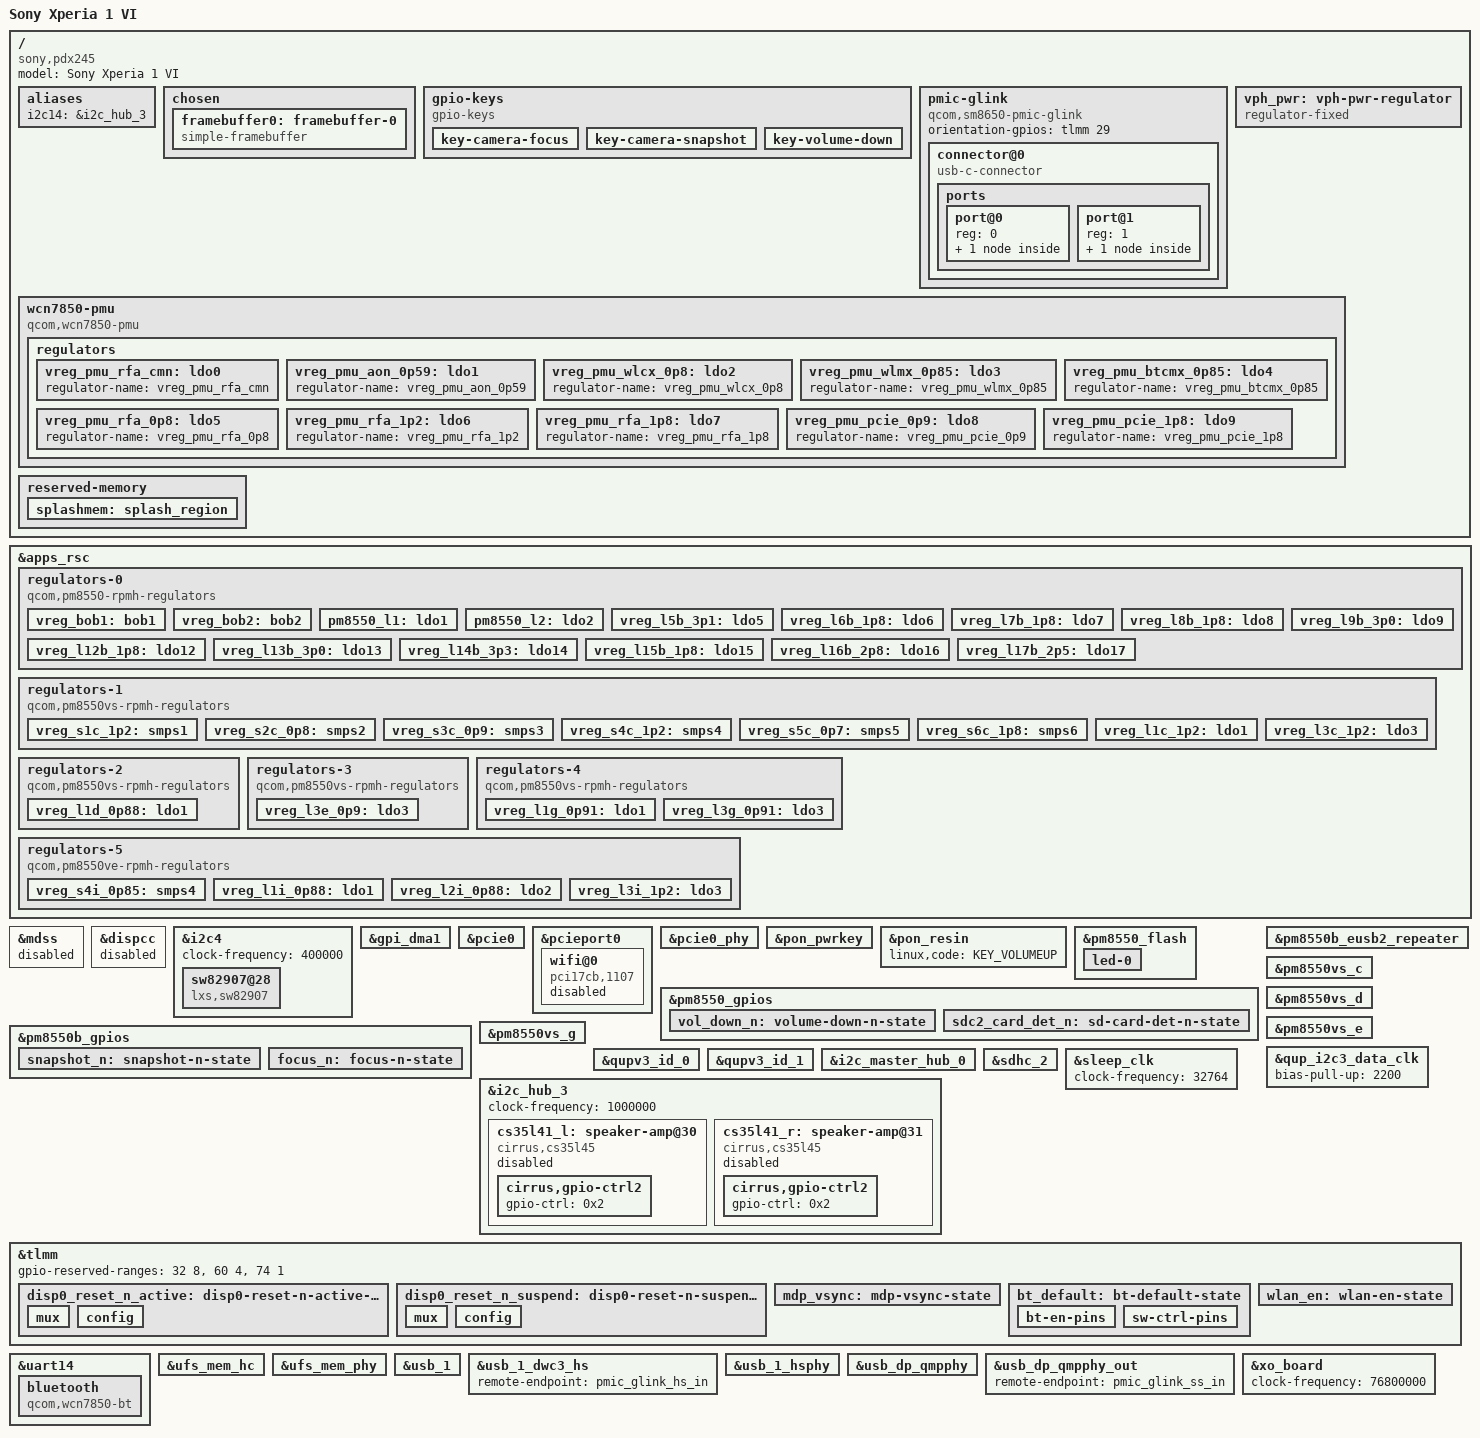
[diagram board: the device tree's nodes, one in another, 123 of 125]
// SPDX-License-Identifier: GPL-2.0 OR BSD-3-Clause
/*
 * Sony Xperia 1 VI (pdx245/XQ-EC54) device tree source
 *
 * Copyright (c) 2026, Igor Belwon <igor.belwon@mentallysanemainliners.org>
 */

/dts-v1/;

#include <dt-bindings/leds/common.h>
#include <dt-bindings/regulator/qcom,rpmh-regulator.h>
#include <dt-bindings/sound/cs35l45.h>
#include "sm8650.dtsi"
#include "pm8010.dtsi"
#include "pm8550.dtsi"
#include "pm8550b.dtsi"
#define PMK8550VE_SID 8
#include "pm8550ve.dtsi"
#include "pm8550vs.dtsi"
#include "pmk8550.dtsi"
#include "pmr735d_a.dtsi"

/ {
	model = "Sony Xperia 1 VI";
	compatible = "sony,pdx245", "qcom,sm8650";

	aliases {
		i2c14 = &i2c_hub_3;
	};

	chosen {
		bootargs = "clk_ignore_unused pd_ignore_unused console=tty0";
		#address-cells = <2>;
		#size-cells = <2>;
		ranges;

		stdout-path = "framebuffer0";

		framebuffer0: framebuffer-0 {
			compatible = "simple-framebuffer";
			memory-region = <&splashmem>;

			width = <1080>;
			height = <2340>;
			stride = <(1080 * 4)>;
			format = "a8r8g8b8";
		};
	};

	gpio-keys {
		compatible = "gpio-keys";
		label = "gpio-keys";

		pinctrl-0 = <&focus_n &snapshot_n &vol_down_n>;
		pinctrl-names = "default";

		key-camera-focus {
			label = "Camera Focus";
			linux,code = <KEY_CAMERA_FOCUS>;
			gpios = <&pm8550b_gpios 8 GPIO_ACTIVE_LOW>;
			debounce-interval = <15>;
			linux,can-disable;
			wakeup-source;
		};

		key-camera-snapshot {
			label = "Camera Snapshot";
			gpios = <&pm8550b_gpios 7 GPIO_ACTIVE_LOW>;
			linux,code = <KEY_CAMERA>;
			debounce-interval = <15>;
			linux,can-disable;
			wakeup-source;
		};

		key-volume-down {
			label = "Volume Down";
			linux,code = <KEY_VOLUMEDOWN>;
			gpios = <&pm8550_gpios 6 GPIO_ACTIVE_LOW>;
			debounce-interval = <15>;
			linux,can-disable;
			wakeup-source;
		};
	};

	pmic-glink {
		compatible = "qcom,sm8650-pmic-glink",
			     "qcom,sm8550-pmic-glink",
			     "qcom,pmic-glink";
		orientation-gpios = <&tlmm 29 GPIO_ACTIVE_HIGH>;
		#address-cells = <1>;
		#size-cells = <0>;

		connector@0 {
			compatible = "usb-c-connector";
			reg = <0>;
			power-role = "dual";
			data-role = "dual";

			ports {
				#address-cells = <1>;
				#size-cells = <0>;

				port@0 {
					reg = <0>;

					pmic_glink_hs_in: endpoint {
						remote-endpoint = <&usb_1_dwc3_hs>;
					};
				};

				port@1 {
					reg = <1>;

					pmic_glink_ss_in: endpoint {
						remote-endpoint = <&usb_dp_qmpphy_out>;
					};
				};
			};
		};
	};

	vph_pwr: vph-pwr-regulator {
		compatible = "regulator-fixed";

		regulator-name = "vph_pwr";
		regulator-min-microvolt = <3700000>;
		regulator-max-microvolt = <3700000>;

		regulator-always-on;
		regulator-boot-on;
	};

	wcn7850-pmu {
		compatible = "qcom,wcn7850-pmu";

		pinctrl-names = "default";
		pinctrl-0 = <&wlan_en>, <&bt_default>;

		wlan-enable-gpios = <&tlmm 16 GPIO_ACTIVE_HIGH>;
		bt-enable-gpios = <&tlmm 17 GPIO_ACTIVE_HIGH>;

		vdd-supply = <&vreg_s4i_0p85>;
		vddio-supply = <&vreg_l15b_1p8>;
		vddio1p2-supply = <&vreg_l3c_1p2>;
		vddaon-supply = <&vreg_s2c_0p8>;
		vdddig-supply = <&vreg_s3c_0p9>;
		vddrfa1p2-supply = <&vreg_s1c_1p2>;
		vddrfa1p8-supply = <&vreg_s6c_1p8>;

		clocks = <&rpmhcc RPMH_RF_CLK1>;

		regulators {
			vreg_pmu_rfa_cmn: ldo0 {
				regulator-name = "vreg_pmu_rfa_cmn";
			};

			vreg_pmu_aon_0p59: ldo1 {
				regulator-name = "vreg_pmu_aon_0p59";
			};

			vreg_pmu_wlcx_0p8: ldo2 {
				regulator-name = "vreg_pmu_wlcx_0p8";
			};

			vreg_pmu_wlmx_0p85: ldo3 {
				regulator-name = "vreg_pmu_wlmx_0p85";
			};

			vreg_pmu_btcmx_0p85: ldo4 {
				regulator-name = "vreg_pmu_btcmx_0p85";
			};

			vreg_pmu_rfa_0p8: ldo5 {
				regulator-name = "vreg_pmu_rfa_0p8";
			};

			vreg_pmu_rfa_1p2: ldo6 {
				regulator-name = "vreg_pmu_rfa_1p2";
			};

			vreg_pmu_rfa_1p8: ldo7 {
				regulator-name = "vreg_pmu_rfa_1p8";
			};

			vreg_pmu_pcie_0p9: ldo8 {
				regulator-name = "vreg_pmu_pcie_0p9";
			};

			vreg_pmu_pcie_1p8: ldo9 {
				regulator-name = "vreg_pmu_pcie_1p8";
			};
		};
	};

	reserved-memory {
		splashmem: splash_region {
			reg = <0x00 0xd5100000 0x00 0x2b00000>;
			no-map;
		};
	};
};

&apps_rsc {
	regulators-0 {
		compatible = "qcom,pm8550-rpmh-regulators";

		vdd-bob1-supply = <&vph_pwr>;
		vdd-bob2-supply = <&vph_pwr>;
		vdd-l2-l13-l14-supply = <&vreg_bob1>;
		vdd-l3-supply = <&vreg_s1c_1p2>;
		vdd-l5-l16-supply = <&vreg_bob1>;
		vdd-l6-l7-supply = <&vreg_bob1>;
		vdd-l8-l9-supply = <&vreg_bob1>;
		vdd-l11-supply = <&vreg_s1c_1p2>;
		vdd-l12-supply = <&vreg_s6c_1p8>;
		vdd-l15-supply = <&vreg_s6c_1p8>;
		vdd-l17-supply = <&vreg_bob2>;

		qcom,pmic-id = "b";

		vreg_bob1: bob1 {
			regulator-name = "vreg_bob1";
			regulator-min-microvolt = <3400000>;
			regulator-max-microvolt = <3960000>;
			regulator-initial-mode = <RPMH_REGULATOR_MODE_HPM>;
		};

		vreg_bob2: bob2 {
			regulator-name = "vreg_bob2";
			regulator-min-microvolt = <2704000>;
			regulator-max-microvolt = <3008000>;
			regulator-initial-mode = <RPMH_REGULATOR_MODE_HPM>;
		};

		pm8550_l1: ldo1 {
			regulator-name = "pm8550_l1";
			regulator-min-microvolt = <1800000>;
			regulator-max-microvolt = <1800000>;
			regulator-initial-mode = <RPMH_REGULATOR_MODE_HPM>;
		};

		pm8550_l2: ldo2 {
			regulator-name = "pm8550_l2";
			regulator-min-microvolt = <3008000>;
			regulator-max-microvolt = <3008000>;
			regulator-initial-mode = <RPMH_REGULATOR_MODE_HPM>;
		};

		vreg_l5b_3p1: ldo5 {
			regulator-name = "vreg_l5b_3p1";
			regulator-min-microvolt = <3104000>;
			regulator-max-microvolt = <3104000>;
			regulator-initial-mode = <RPMH_REGULATOR_MODE_HPM>;
			regulator-allow-set-load;
			regulator-allowed-modes = <RPMH_REGULATOR_MODE_LPM
						   RPMH_REGULATOR_MODE_HPM>;
		};

		vreg_l6b_1p8: ldo6 {
			regulator-name = "vreg_l6b_1p8";
			regulator-min-microvolt = <1800000>;
			regulator-max-microvolt = <3008000>;
			regulator-initial-mode = <RPMH_REGULATOR_MODE_HPM>;
			regulator-allow-set-load;
			regulator-allowed-modes = <RPMH_REGULATOR_MODE_LPM
						   RPMH_REGULATOR_MODE_HPM>;
		};

		vreg_l7b_1p8: ldo7 {
			regulator-name = "vreg_l7b_1p8";
			regulator-min-microvolt = <1800000>;
			regulator-max-microvolt = <3008000>;
			regulator-initial-mode = <RPMH_REGULATOR_MODE_HPM>;
		};

		vreg_l8b_1p8: ldo8 {
			regulator-name = "vreg_l8b_1p8";
			regulator-min-microvolt = <1800000>;
			regulator-max-microvolt = <3008000>;
			regulator-initial-mode = <RPMH_REGULATOR_MODE_HPM>;
			regulator-allow-set-load;
			regulator-allowed-modes = <RPMH_REGULATOR_MODE_LPM
						   RPMH_REGULATOR_MODE_HPM>;
		};

		vreg_l9b_3p0: ldo9 {
			regulator-name = "pm8550_l9";
			regulator-min-microvolt = <2960000>;
			regulator-max-microvolt = <3008000>;
			regulator-initial-mode = <RPMH_REGULATOR_MODE_HPM>;
		};

		vreg_l12b_1p8: ldo12 {
			regulator-name = "vreg_l12b_1p8";
			regulator-min-microvolt = <1800000>;
			regulator-max-microvolt = <1800000>;
			regulator-initial-mode = <RPMH_REGULATOR_MODE_HPM>;
			regulator-allow-set-load;
			regulator-allowed-modes = <RPMH_REGULATOR_MODE_LPM
						   RPMH_REGULATOR_MODE_HPM>;
		};

		vreg_l13b_3p0: ldo13 {
			regulator-name = "vreg_l13b_3p0";
			regulator-min-microvolt = <3000000>;
			regulator-max-microvolt = <3000000>;
			regulator-initial-mode = <RPMH_REGULATOR_MODE_HPM>;
			regulator-allow-set-load;
			regulator-allowed-modes = <RPMH_REGULATOR_MODE_LPM
						   RPMH_REGULATOR_MODE_HPM>;
		};

		vreg_l14b_3p3: ldo14 {
			regulator-name = "vreg_l14b_3p3";
			regulator-min-microvolt = <3008000>;
			regulator-max-microvolt = <3008000>;
			regulator-initial-mode = <RPMH_REGULATOR_MODE_HPM>;
			regulator-allow-set-load;
			regulator-allowed-modes = <RPMH_REGULATOR_MODE_LPM
						   RPMH_REGULATOR_MODE_HPM>;
		};

		vreg_l15b_1p8: ldo15 {
			regulator-name = "vreg_l15b_1p8";
			regulator-min-microvolt = <1800000>;
			regulator-max-microvolt = <1800000>;
			regulator-initial-mode = <RPMH_REGULATOR_MODE_HPM>;
			regulator-allow-set-load;
			regulator-allowed-modes = <RPMH_REGULATOR_MODE_LPM
						   RPMH_REGULATOR_MODE_HPM>;
		};

		vreg_l16b_2p8: ldo16 {
			regulator-name = "vreg_l16b_2p8";
			regulator-min-microvolt = <2800000>;
			regulator-max-microvolt = <2800000>;
			regulator-initial-mode = <RPMH_REGULATOR_MODE_HPM>;
			regulator-allow-set-load;
			regulator-allowed-modes = <RPMH_REGULATOR_MODE_LPM
						   RPMH_REGULATOR_MODE_HPM>;
		};

		vreg_l17b_2p5: ldo17 {
			regulator-name = "vreg_l17b_2p5";
			regulator-min-microvolt = <2504000>;
			regulator-max-microvolt = <2504000>;
			regulator-initial-mode = <RPMH_REGULATOR_MODE_HPM>;
			regulator-allow-set-load;
			regulator-allowed-modes = <RPMH_REGULATOR_MODE_LPM
						   RPMH_REGULATOR_MODE_HPM>;
		};
	};

	regulators-1 {
		compatible = "qcom,pm8550vs-rpmh-regulators";

		vdd-l1-supply = <&vreg_s1c_1p2>;
		vdd-l2-supply = <&vreg_s1c_1p2>;
		vdd-l3-supply = <&vreg_s1c_1p2>;
		vdd-s1-supply = <&vph_pwr>;
		vdd-s2-supply = <&vph_pwr>;
		vdd-s3-supply = <&vph_pwr>;
		vdd-s4-supply = <&vph_pwr>;
		vdd-s5-supply = <&vph_pwr>;
		vdd-s6-supply = <&vph_pwr>;

		qcom,pmic-id = "c";

		vreg_s1c_1p2: smps1 {
			regulator-name = "vreg_s1c_1p2";
			regulator-min-microvolt = <1224000>;
			regulator-max-microvolt = <1348000>;
			regulator-initial-mode = <RPMH_REGULATOR_MODE_HPM>;
		};

		vreg_s2c_0p8: smps2 {
			regulator-name = "vreg_s2c_0p8";
			regulator-min-microvolt = <500000>;
			regulator-max-microvolt = <1036000>;
			regulator-initial-mode = <RPMH_REGULATOR_MODE_HPM>;
		};

		vreg_s3c_0p9: smps3 {
			regulator-name = "vreg_s3c_0p9";
			regulator-min-microvolt = <904000>;
			regulator-max-microvolt = <1064000>;
			regulator-initial-mode = <RPMH_REGULATOR_MODE_HPM>;
		};

		vreg_s4c_1p2: smps4 {
			regulator-name = "vreg_s4c_1p2";
			regulator-min-microvolt = <1200000>;
			regulator-max-microvolt = <1280000>;
			regulator-initial-mode = <RPMH_REGULATOR_MODE_HPM>;
		};

		vreg_s5c_0p7: smps5 {
			regulator-name = "vreg_s5c_0p7";
			regulator-min-microvolt = <300000>;
			regulator-max-microvolt = <900000>;
			regulator-initial-mode = <RPMH_REGULATOR_MODE_HPM>;
		};

		vreg_s6c_1p8: smps6 {
			regulator-name = "vreg_s6c_1p8";
			regulator-min-microvolt = <1856000>;
			regulator-max-microvolt = <2000000>;
			regulator-initial-mode = <RPMH_REGULATOR_MODE_HPM>;
		};

		vreg_l1c_1p2: ldo1 {
			regulator-name = "vreg_l1c_1p2";
			regulator-min-microvolt = <1200000>;
			regulator-max-microvolt = <1200000>;
			regulator-initial-mode = <RPMH_REGULATOR_MODE_HPM>;
			regulator-allow-set-load;
			regulator-allowed-modes = <RPMH_REGULATOR_MODE_LPM
						   RPMH_REGULATOR_MODE_HPM>;
		};

		vreg_l3c_1p2: ldo3 {
			regulator-name = "vreg_l3c_1p2";
			regulator-min-microvolt = <1200000>;
			regulator-max-microvolt = <1200000>;
			regulator-initial-mode = <RPMH_REGULATOR_MODE_HPM>;
			regulator-allow-set-load;
			regulator-allowed-modes = <RPMH_REGULATOR_MODE_LPM
						   RPMH_REGULATOR_MODE_HPM>;
		};
	};

	regulators-2 {
		compatible = "qcom,pm8550vs-rpmh-regulators";

		vdd-l1-supply = <&vreg_s3c_0p9>;

		qcom,pmic-id = "d";

		vreg_l1d_0p88: ldo1 {
			regulator-name = "vreg_l1d_0p88";
			regulator-min-microvolt = <880000>;
			regulator-max-microvolt = <920000>;
			regulator-initial-mode = <RPMH_REGULATOR_MODE_HPM>;
			regulator-allow-set-load;
			regulator-allowed-modes = <RPMH_REGULATOR_MODE_LPM
						   RPMH_REGULATOR_MODE_HPM>;
		};
	};

	regulators-3 {
		compatible = "qcom,pm8550vs-rpmh-regulators";

		vdd-l3-supply = <&vreg_s3c_0p9>;

		qcom,pmic-id = "e";

		vreg_l3e_0p9: ldo3 {
			regulator-name = "vreg_l3e_0p9";
			regulator-min-microvolt = <880000>;
			regulator-max-microvolt = <920000>;
			regulator-initial-mode = <RPMH_REGULATOR_MODE_HPM>;
			regulator-allow-set-load;
			regulator-allowed-modes = <RPMH_REGULATOR_MODE_LPM
						   RPMH_REGULATOR_MODE_HPM>;
		};
	};

	regulators-4 {
		compatible = "qcom,pm8550vs-rpmh-regulators";

		vdd-l1-supply = <&vreg_s3c_0p9>;
		vdd-l3-supply = <&vreg_s3c_0p9>;

		qcom,pmic-id = "g";

		vreg_l1g_0p91: ldo1 {
			regulator-name = "vreg_l1g_0p91";
			regulator-min-microvolt = <912000>;
			regulator-max-microvolt = <920000>;
			regulator-initial-mode = <RPMH_REGULATOR_MODE_HPM>;
			regulator-allow-set-load;
			regulator-allowed-modes = <RPMH_REGULATOR_MODE_LPM
						   RPMH_REGULATOR_MODE_HPM>;
		};

		/*vreg_l2g_1p7: ldo2 {
			regulator-name = "vreg_l3g_0p91";
			regulator-min-microvolt = <1700000>;
			regulator-max-microvolt = <1700000>;
			regulator-initial-mode = <RPMH_REGULATOR_MODE_HPM>;
			regulator-allow-set-load;
			regulator-allowed-modes = <RPMH_REGULATOR_MODE_LPM
			RPMH_REGULATOR_MODE_HPM>;
		};*/

		vreg_l3g_0p91: ldo3 {
			regulator-name = "vreg_l3g_0p91";
			regulator-min-microvolt = <880000>;
			regulator-max-microvolt = <912000>;
			regulator-initial-mode = <RPMH_REGULATOR_MODE_HPM>;
			regulator-allow-set-load;
			regulator-allowed-modes = <RPMH_REGULATOR_MODE_LPM
						   RPMH_REGULATOR_MODE_HPM>;
		};
	};

	regulators-5 {
		compatible = "qcom,pm8550ve-rpmh-regulators";

		vdd-l1-supply = <&vreg_s3c_0p9>;
		vdd-l2-supply = <&vreg_s3c_0p9>;
		vdd-l3-supply = <&vreg_s1c_1p2>;
		vdd-s4-supply = <&vph_pwr>;

		qcom,pmic-id = "i";

		vreg_s4i_0p85: smps4 {
			regulator-name = "vreg_s4i_0p85";
			regulator-min-microvolt = <300000>;
			regulator-max-microvolt = <1004000>;
			regulator-initial-mode = <RPMH_REGULATOR_MODE_HPM>;
		};

		vreg_l1i_0p88: ldo1 {
			regulator-name = "vreg_l1i_0p88";
			regulator-min-microvolt = <880000>;
			regulator-max-microvolt = <912000>;
			regulator-initial-mode = <RPMH_REGULATOR_MODE_HPM>;
			regulator-allow-set-load;
			regulator-allowed-modes = <RPMH_REGULATOR_MODE_LPM
						   RPMH_REGULATOR_MODE_HPM>;
		};

		vreg_l2i_0p88: ldo2 {
			regulator-name = "vreg_l2i_0p88";
			regulator-min-microvolt = <880000>;
			regulator-max-microvolt = <912000>;
			regulator-initial-mode = <RPMH_REGULATOR_MODE_HPM>;
			regulator-allow-set-load;
			regulator-allowed-modes = <RPMH_REGULATOR_MODE_LPM
						   RPMH_REGULATOR_MODE_HPM>;
		};

		vreg_l3i_1p2: ldo3 {
			regulator-name = "vreg_l3i_0p91";
			regulator-min-microvolt = <1200000>;
			regulator-max-microvolt = <1200000>;
			regulator-initial-mode = <RPMH_REGULATOR_MODE_HPM>;
			regulator-allow-set-load;
			regulator-allowed-modes = <RPMH_REGULATOR_MODE_LPM
						   RPMH_REGULATOR_MODE_HPM>;
		};
	};

	/* m, n fail to register */
};

&mdss {
	status = "disabled";
};

&dispcc {
	status = "disabled";
};

&i2c4  {
	status = "okay";
	clock-frequency = <400000>;

	sw82907@28 {
		status = "okay";
		compatible = "lxs,sw82907";
		reg = <0x28>;


		reset-gpio = <&tlmm 161 GPIO_ACTIVE_LOW>;
		irq-gpio = <&tlmm 162 GPIO_ACTIVE_LOW>;

		max_x = <1080>;
		max_y = <2340>;

		// enable firmware control
		use_firmware = <1>;

		// auto-update during driver initialization
		use_fw_upgrade = <1>;
		use_fw_ver_diff = <1>;

		// watchdog
		watchdog_support = <1>;
		watchdog_delay_ms = <10000>;

		// enable knock
		use_lpwg = <1>;
		pt_open_cmp = <4800 8192>;
		pt_short_gnd_cmp = <6500 8192>;
		pt_short_trx_cmp = <6500 8192>;
		pt_short_vdd_cmp = <0 5200>;

		// grip rejection
		lxs,rejection_area_portrait = <25 140 60 190>;
		lxs,rejection_area_landscape = <150 20 200 60>;
		lxs,rejection_area_portrait_ge = <200 200>;
		lxs,rejection_area_landscape_ge = <200 200 200 200>;

		fw_image = "touch_module_id_0x03.img";
	};
};

/*
&mdss {
	status = "okay";
};


&mdss_dsi0 {
	//vdda-supply = <&vreg_l3i_1p2>;

	status = "okay";

	panel@0 {
		compatible = "mdss,sony_unc";
		reg = <0>;

		reset-gpios = <&tlmm 133 GPIO_ACTIVE_LOW>;

		vddio-supply = <&vreg_l12b_1p8>;
		vci-supply = <&vreg_l13b_3p0>;
		//vddr-supply = <&vreg_l2g_1p7>;

		pinctrl-0 = <&disp0_reset_n_active>, <&mdp_vsync>;
		pinctrl-1 = <&disp0_reset_n_suspend>, <&mdp_vsync>;
		pinctrl-names = "default", "sleep";

		port {
			panel0_in: endpoint {
				remote-endpoint = <&mdss_dsi0_out>;
			};
		};
	};
};

&mdss_dsi0_out {
	remote-endpoint = <&panel0_in>;
	data-lanes = <0 1 2 3>;
};


&mdss_dsi0_phy {
	vdds-supply = <&vreg_l1i_0p88>;

	status = "okay";
};
*/
&gpi_dma1 {
	status = "okay";
};

&pcie0 {
	wake-gpios = <&tlmm 96 GPIO_ACTIVE_HIGH>;
	perst-gpios = <&tlmm 94 GPIO_ACTIVE_LOW>;

	pinctrl-0 = <&pcie0_default_state>;
	pinctrl-names = "default";

	status = "okay";
};

&pcieport0 {
	wifi@0 {
		status = "fail"; // failed to set mhi state: POWER_ON(2) NO FIRMWARE?
		compatible = "pci17cb,1107";
		reg = <0x10000 0x0 0x0 0x0 0x0>;

		vddrfacmn-supply = <&vreg_pmu_rfa_cmn>;
		vddaon-supply = <&vreg_pmu_aon_0p59>;
		vddwlcx-supply = <&vreg_pmu_wlcx_0p8>;
		vddwlmx-supply = <&vreg_pmu_wlmx_0p85>;
		vddrfa0p8-supply = <&vreg_pmu_rfa_0p8>;
		vddrfa1p2-supply = <&vreg_pmu_rfa_1p2>;
		vddrfa1p8-supply = <&vreg_pmu_rfa_1p8>;
		vddpcie0p9-supply = <&vreg_pmu_pcie_0p9>;
		vddpcie1p8-supply = <&vreg_pmu_pcie_1p8>;
	};
};

&pcie0_phy {
	vdda-phy-supply = <&vreg_l1i_0p88>;
	vdda-pll-supply = <&vreg_l3i_1p2>;

	status = "okay";
};

&pon_pwrkey {
	status = "okay";
};

&pon_resin {
	linux,code = <KEY_VOLUMEUP>;

	status = "okay";
};

&pm8550_flash {
	status = "okay";

	led-0 {
		function = LED_FUNCTION_FLASH;
		color = <LED_COLOR_ID_YELLOW>;
		led-sources = <1>, <4>;
		led-max-microamp = <500000>;
		flash-max-microamp = <2000000>;
		flash-max-timeout-us = <1280000>;
		function-enumerator = <0>;
	};
};

&pm8550_gpios {
	vol_down_n: volume-down-n-state {
		pins = "gpio6";
		function = "normal";
		power-source = <1>;
		bias-pull-up;
		input-enable;
	};

	sdc2_card_det_n: sd-card-det-n-state {
		pins = "gpio12";
		function = "normal";
		power-source = <1>;
		bias-pull-down;
		output-disable;
		input-enable;
	};
};

&pm8550b_eusb2_repeater {
	qcom,tune-usb2-disc-thres = /bits/ 8 <0x6>;
	qcom,tune-usb2-amplitude = /bits/ 8 <0xf>;
	qcom,tune-usb2-preem = /bits/ 8 <0x7>;
	vdd18-supply = <&vreg_l15b_1p8>;
	vdd3-supply = <&vreg_l5b_3p1>;
};

&pm8550b_gpios {
	snapshot_n: snapshot-n-state {
		pins = "gpio7";
		function = "normal";
		power-source = <1>;
		bias-pull-up;
		input-enable;
	};

	focus_n: focus-n-state {
		pins = "gpio8";
		function = "normal";
		power-source = <1>;
		bias-pull-up;
		input-enable;
	};
};

&pm8550vs_c {
	status = "okay";
};

&pm8550vs_d {
	status = "okay";
};

&pm8550vs_e {
	status = "okay";
};

&pm8550vs_g {
	status = "okay";
};

&qup_i2c3_data_clk {
	bias-pull-up = <2200>;
};

&qupv3_id_0 {
	status = "okay";
};

&qupv3_id_1 {
	status = "okay";
};

&i2c_master_hub_0 {
	status = "okay";
};

&i2c_hub_3 {
	clock-frequency = <1000000>;
	status = "okay";

	// both cs35l45: Timeout waiting for OTP boot
	cs35l41_l: speaker-amp@30 {
		compatible = "cirrus,cs35l45";
		reg = <0x30>;
		interrupts-extended = <&tlmm 182 IRQ_TYPE_LEVEL_LOW>;
		reset-gpios = <&tlmm 183 GPIO_ACTIVE_HIGH>;
		cirrus,asp-sdout-hiz-ctrl = <(CS35L45_ASP_TX_HIZ_UNUSED | CS35L45_ASP_TX_HIZ_DISABLED)>;
		#sound-dai-cells = <1>;

		status = "fail";

		cirrus,gpio-ctrl2 {
			gpio-ctrl = <0x2>;
		};
	};

	cs35l41_r: speaker-amp@31 {
		compatible = "cirrus,cs35l45";
		reg = <0x31>;
		interrupts-extended = <&tlmm 182 IRQ_TYPE_LEVEL_LOW>;
		reset-gpios = <&tlmm 183 GPIO_ACTIVE_HIGH>;
		cirrus,asp-sdout-hiz-ctrl = <(CS35L45_ASP_TX_HIZ_UNUSED | CS35L45_ASP_TX_HIZ_DISABLED)>;
		#sound-dai-cells = <1>;

		status = "fail";

		cirrus,gpio-ctrl2 {
			gpio-ctrl = <0x2>;
		};
	};
};

/* remote processors, ipa need firmware which is not packaged yet

&ipa {
	qcom,gsi-loader = "self";
	memory-region = <&ipa_fw_mem>;
	firmware-name = "qcom/sm8650/ipa_fws.mbn";
	status = "okay";
};

&remoteproc_adsp {
	firmware-name = "qcom/sm8650/adsp.mbn",
			"qcom/sm8650/adsp_dtb.mbn";

	status = "okay";
};

&remoteproc_cdsp {
	firmware-name = "qcom/sm8650/cdsp.mbn",
			"qcom/sm8650/cdsp_dtb.mbn";

	status = "okay";
};

&remoteproc_mpss {
	firmware-name = "qcom/sm8650/modem.mbn",
			"qcom/sm8650/modem_dtb.mbn";

	status = "okay";
};
*/

&sdhc_2 {
	cd-gpios = <&pm8550_gpios 12 GPIO_ACTIVE_HIGH>;
	pinctrl-0 = <&sdc2_default &sdc2_card_det_n>;
	pinctrl-1 = <&sdc2_sleep &sdc2_card_det_n>;
	pinctrl-names = "default", "sleep";
	vmmc-supply = <&vreg_l9b_3p0>;
	vqmmc-supply = <&vreg_l8b_1p8>;
	no-sdio;
	no-mmc;
	status = "okay";
};

&sleep_clk {
	clock-frequency = <32764>;
};

&tlmm {
	/* Reserved I/Os for NFC */
	gpio-reserved-ranges = <32 8>, <60 4>, <74 1>; // maybe 32 -> 36 and 8 ->4?

	disp0_reset_n_active: disp0-reset-n-active-state {
		mux {
			pins = "gpio133";
			function = "gpio";
		};

		config {
			pins = "gpio133";
			drive-strength = <2>;
			bias-disable;
		};
	};

	disp0_reset_n_suspend: disp0-reset-n-suspend-state {
		mux {
			pins = "gpio133";
			function = "gpio";
		};

		config {
			pins = "gpio133";
			drive-strength = <2>;
			bias-disable;
		};
	};

	mdp_vsync: mdp-vsync-state {
		pins = "gpio86";
		function = "mdp_vsync";
		drive-strength = <2>;
		bias-pull-down;
	};

	bt_default: bt-default-state {
		bt-en-pins {
			pins = "gpio17";
			function = "gpio";
			drive-strength = <16>;
			bias-disable;
		};

		sw-ctrl-pins {
			pins = "gpio18";
			function = "gpio";
			bias-pull-down;
		};
	};

	wlan_en: wlan-en-state {
		pins = "gpio16";
		function = "gpio";
		drive-strength = <8>;
		bias-pull-down;
	};
};

&uart14 {
	status = "okay";

	bluetooth {
		compatible = "qcom,wcn7850-bt";

		vddrfacmn-supply = <&vreg_pmu_rfa_cmn>;
		vddaon-supply = <&vreg_pmu_aon_0p59>;
		vddwlcx-supply = <&vreg_pmu_wlcx_0p8>;
		vddwlmx-supply = <&vreg_pmu_wlmx_0p85>;
		vddrfa0p8-supply = <&vreg_pmu_rfa_0p8>;
		vddrfa1p2-supply = <&vreg_pmu_rfa_1p2>;
		vddrfa1p8-supply = <&vreg_pmu_rfa_1p8>;

		max-speed = <3200000>;
	};
};

&ufs_mem_hc {
	reset-gpios = <&tlmm 210 GPIO_ACTIVE_LOW>;

	vcc-supply = <&vreg_l17b_2p5>;
	vcc-max-microamp = <1300000>;
	vccq-supply = <&vreg_l1c_1p2>;
	vccq-max-microamp = <1200000>;

	status = "okay";
};

&ufs_mem_phy {
	vdda-phy-supply = <&vreg_l1d_0p88>;
	vdda-pll-supply = <&vreg_l3i_1p2>;

	status = "okay";
};

&usb_1 {
	dr_mode = "otg";
	usb-role-switch;

	status = "okay";
};

&usb_1_dwc3_hs {
	remote-endpoint = <&pmic_glink_hs_in>;
};

&usb_1_hsphy {
	vdd-supply = <&vreg_l1i_0p88>;
	vdda12-supply = <&vreg_l3i_1p2>;

	phys = <&pm8550b_eusb2_repeater>;

	status = "okay";
};

&usb_dp_qmpphy {
	vdda-phy-supply = <&vreg_l3i_1p2>;
	vdda-pll-supply = <&vreg_l3g_0p91>;

	status = "okay";
};

&usb_dp_qmpphy_out {
	remote-endpoint = <&pmic_glink_ss_in>;
};

&xo_board {
	clock-frequency = <76800000>;
};
